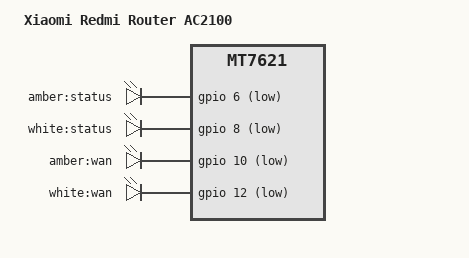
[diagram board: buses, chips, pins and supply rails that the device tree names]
// SPDX-License-Identifier: GPL-2.0-or-later OR MIT

#include "mt7621_xiaomi_router-ac2100.dtsi"

/ {
	compatible = "xiaomi,redmi-router-ac2100", "mediatek,mt7621-soc";
	model = "Xiaomi Redmi Router AC2100";

	aliases {
		led-boot = &led_status_amber;
		led-failsafe = &led_status_amber;
		led-running = &led_status_white;
		led-upgrade = &led_status_white;
		label-mac-device = &gmac0;
	};

	leds {
		compatible = "gpio-leds";

		led_status_amber: status_amber {
			label = "amber:status";
			gpios = <&gpio 6 GPIO_ACTIVE_LOW>;
		};

		led_status_white: status_white {
			label = "white:status";
			gpios = <&gpio 8 GPIO_ACTIVE_LOW>;
		};

		wan_amber {
			label = "amber:wan";
			gpios = <&gpio 10 GPIO_ACTIVE_LOW>;
		};

		wan_white {
			label = "white:wan";
			gpios = <&gpio 12 GPIO_ACTIVE_LOW>;
		};
	};
};
